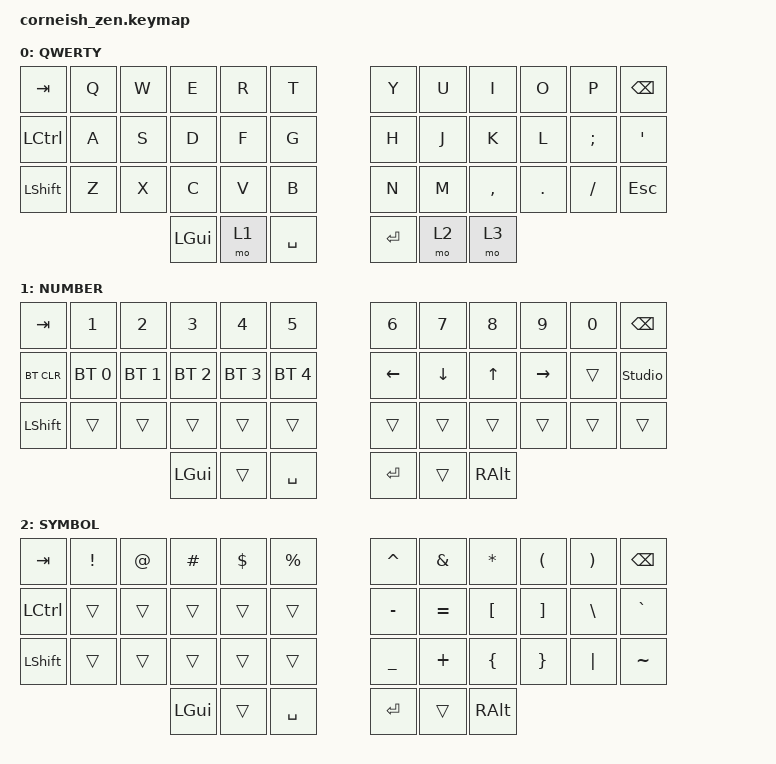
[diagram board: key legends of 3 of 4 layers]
#include <behaviors.dtsi>
#include <dt-bindings/zmk/keys.h>
#include <dt-bindings/zmk/bt.h>

/ {
    chosen {
        zmk,physical-layout = &foostan_corne_6col_layout;
        // zmk,physical-layout = &foostan_corne_5col_layout;
    };

    /* ========================== */
    /*  MACRO ALT-CODES WINDOWS   */
    /* ========================== */
    macros {
        /* Consigli: piccole attese rendono gli Alt-codes molto affidabili */
        /* à (Alt+0224)  /  À (Alt+0192) */
        agrave_alt: agrave_alt {
            compatible = "zmk,behavior-macro";
            #binding-cells = <0>;
            wait-ms = <40>; tap-ms = <40>;
            bindings = <&macro_press &kp LALT>,
                       <&macro_tap &kp KP_N0 &kp KP_N2 &kp KP_N2 &kp KP_N4>,
                       <&macro_release &kp LALT>;
        };
        Agrave_alt: Agrave_alt {
            compatible = "zmk,behavior-macro";
            #binding-cells = <0>;
            wait-ms = <40>; tap-ms = <40>;
            bindings = <&macro_press &kp LALT>,
                       <&macro_tap &kp KP_N0 &kp KP_N1 &kp KP_N9 &kp KP_N2>,
                       <&macro_release &kp LALT>;
        };

        /* è (Alt+0232)  /  È (Alt+0200) */
        egrave_alt: egrave_alt {
            compatible = "zmk,behavior-macro";
            #binding-cells = <0>;
            wait-ms = <40>; tap-ms = <40>;
            bindings = <&macro_press &kp LALT>,
                       <&macro_tap &kp KP_N0 &kp KP_N2 &kp KP_N3 &kp KP_N2>,
                       <&macro_release &kp LALT>;
        };
        Egrave_alt: Egrave_alt {
            compatible = "zmk,behavior-macro";
            #binding-cells = <0>;
            wait-ms = <40>; tap-ms = <40>;
            bindings = <&macro_press &kp LALT>,
                       <&macro_tap &kp KP_N0 &kp KP_N2 &kp KP_N0 &kp KP_N0>,
                       <&macro_release &kp LALT>;
        };

        /* ì (Alt+0236)  /  Ì (Alt+0204) */
        igrave_alt: igrave_alt {
            compatible = "zmk,behavior-macro";
            #binding-cells = <0>;
            wait-ms = <40>; tap-ms = <40>;
            bindings = <&macro_press &kp LALT>,
                       <&macro_tap &kp KP_N0 &kp KP_N2 &kp KP_N3 &kp KP_N6>,
                       <&macro_release &kp LALT>;
        };
        Igrave_alt: Igrave_alt {
            compatible = "zmk,behavior-macro";
            #binding-cells = <0>;
            wait-ms = <40>; tap-ms = <40>;
            bindings = <&macro_press &kp LALT>,
                       <&macro_tap &kp KP_N0 &kp KP_N2 &kp KP_N0 &kp KP_N4>,
                       <&macro_release &kp LALT>;
        };

        /* ò (Alt+0242)  /  Ò (Alt+0210) */
        ograve_alt: ograve_alt {
            compatible = "zmk,behavior-macro";
            #binding-cells = <0>;
            wait-ms = <40>; tap-ms = <40>;
            bindings = <&macro_press &kp LALT>,
                       <&macro_tap &kp KP_N0 &kp KP_N2 &kp KP_N4 &kp KP_N2>,
                       <&macro_release &kp LALT>;
        };
        Ograve_alt: Ograve_alt {
            compatible = "zmk,behavior-macro";
            #binding-cells = <0>;
            wait-ms = <40>; tap-ms = <40>;
            bindings = <&macro_press &kp LALT>,
                       <&macro_tap &kp KP_N0 &kp KP_N2 &kp KP_N1 &kp KP_N0>,
                       <&macro_release &kp LALT>;
        };

        /* ù (Alt+0249)  /  Ù (Alt+0217) */
        ugrave_alt: ugrave_alt {
            compatible = "zmk,behavior-macro";
            #binding-cells = <0>;
            wait-ms = <40>; tap-ms = <40>;
            bindings = <&macro_press &kp LALT>,
                       <&macro_tap &kp KP_N0 &kp KP_N2 &kp KP_N4 &kp KP_N9>,
                       <&macro_release &kp LALT>;
        };
        Ugrave_alt: Ugrave_alt {
            compatible = "zmk,behavior-macro";
            #binding-cells = <0>;
            wait-ms = <40>; tap-ms = <40>;
            bindings = <&macro_press &kp LALT>,
                       <&macro_tap &kp KP_N0 &kp KP_N2 &kp KP_N1 &kp KP_N7>,
                       <&macro_release &kp LALT>;
        };
    };

    /* ========================== */
    /*     MOD-MORPH (Shift)      */
    /* ========================== */
    behaviors {
        /* Se è premuto LSHIFT o RSHIFT ⇒ usa la versione maiuscola (macro corrispondente) */
        mm_agrave: mm_agrave {
            compatible = "zmk,behavior-mod-morph";
            #binding-cells = <0>;
            mods = <(MOD_LSFT|MOD_RSFT)>;
            bindings = <&agrave_alt>, <&Agrave_alt>;
        };
        mm_egrave: mm_egrave {
            compatible = "zmk,behavior-mod-morph";
            #binding-cells = <0>;
            mods = <(MOD_LSFT|MOD_RSFT)>;
            bindings = <&egrave_alt>, <&Egrave_alt>;
        };
        mm_igrave: mm_igrave {
            compatible = "zmk,behavior-mod-morph";
            #binding-cells = <0>;
            mods = <(MOD_LSFT|MOD_RSFT)>;
            bindings = <&igrave_alt>, <&Igrave_alt>;
        };
        mm_ograve: mm_ograve {
            compatible = "zmk,behavior-mod-morph";
            #binding-cells = <0>;
            mods = <(MOD_LSFT|MOD_RSFT)>;
            bindings = <&ograve_alt>, <&Ograve_alt>;
        };
        mm_ugrave: mm_ugrave {
            compatible = "zmk,behavior-mod-morph";
            #binding-cells = <0>;
            mods = <(MOD_LSFT|MOD_RSFT)>;
            bindings = <&ugrave_alt>, <&Ugrave_alt>;
        };
    };
};

 / {
    keymap {
        compatible = "zmk,keymap";

        default_layer {
            display-name = "QWERTY";
            // --------------------------------------------------------------------------------
            // |  TAB |  Q  |  W  |  E  |  R  |  T  |   |  Y  |  U   |  I  |  O  |  P  | BSPC |
            // | CTRL |  A  |  S  |  D  |  F  |  G  |   |  H  |  J   |  K  |  L  |  ;  |  '   |
            // | SHFT |  Z  |  X  |  C  |  V  |  B  |   |  N  |  M   |  ,  |  .  |  /  | ESC  |
            //                    | GUI | LWR | SPC |   | ENT | RSE  | ACC |
            // (ACC = &mo 3)
            bindings = <
&kp TAB   &kp Q &kp W &kp E &kp R &kp T   &kp Y &kp U  &kp I     &kp O   &kp P    &kp BSPC
&kp LCTRL &kp A &kp S &kp D &kp F &kp G   &kp H &kp J  &kp K     &kp L   &kp SEMI &kp SQT
&kp LSHFT &kp Z &kp X &kp C &kp V &kp B   &kp N &kp M  &kp COMMA &kp DOT &kp FSLH &kp ESC
               &kp LGUI &mo 1 &kp SPACE   &kp RET &mo 2 &mo 3
            >;
        };

        lower_layer {
            display-name = "NUMBER";
            // -----------------------------------------------------------------------------------------
            // |  TAB |  1  |  2  |  3  |  4  |  5  |   |  6  |  7  |  8  |  9  |  0  | BSPC |
            // | BTCLR| BT1 | BT2 | BT3 | BT4 | BT5 |   | LFT | DWN |  UP | RGT |     |Studio|
            // | SHFT |     |     |     |     |     |   |     |     |     |     |     |      |
            //                    | GUI |     | SPC |   | ENT |     | ALT |
            bindings = <
&kp TAB    &kp N1       &kp N2       &kp N3       &kp N4       &kp N5         &kp N6   &kp N7   &kp N8 &kp N9    &kp N0 &kp BSPC
&bt BT_CLR &bt BT_SEL 0 &bt BT_SEL 1 &bt BT_SEL 2 &bt BT_SEL 3 &bt BT_SEL 4   &kp LEFT &kp DOWN &kp UP &kp RIGHT &trans &studio_unlock
&kp LSHFT  &trans       &trans       &trans       &trans       &trans         &trans   &trans   &trans &trans    &trans &trans
                                     &kp LGUI     &trans       &kp SPACE      &kp RET  &trans   &kp RALT
            >;
        };

        raise_layer {
            display-name = "SYMBOL";
            // -----------------------------------------------------------------------------------------
            // |  TAB |  !  |  @  |  #  |  $  |  %  |   |  ^  |  &  |  *  |  (  |  )  | BSPC |
            // | CTRL |     |     |     |     |     |   |  -  |  =  |  [  |  ]  |  \  |  `   |
            // | SHFT |     |     |     |     |     |   |  _  |  +  |  {  |  }  | "|" |  ~   |
            //                    | GUI |     | SPC |   | ENT |     | ALT |
            bindings = <
&kp  TAB  &kp EXCL &kp AT &kp HASH &kp DLLR &kp PRCNT   &kp CARET &kp AMPS  &kp ASTRK &kp LPAR &kp RPAR &kp BSPC
&kp LCTRL &trans   &trans &trans   &trans   &trans      &kp MINUS &kp EQUAL &kp LBKT  &kp RBKT &kp BSLH &kp GRAVE
&kp LSHFT &trans   &trans &trans   &trans   &trans      &kp UNDER &kp PLUS  &kp LBRC  &kp RBRC &kp PIPE &kp TILDE
                          &kp LGUI &trans   &kp SPACE   &kp RET   &trans    &kp RALT
            >;
        };

        accent_layer {
            display-name = "ACCENTI";
            // --------------------------------------------------------------------------------------------------------------------
            // |      |     |     |  è/È |     |     |   |     |  ù/Ù |  ì/Ì |  ò/Ò |     |       |
            // |      |  à/À|     |      |     |     |   |     |      |      |      |     |       |
            // |      |     |     |      |     |     |   |     |      |      |      |     |       |
            //   (Shift premuto = MAIUSCOLE) – via mod-morph -> macro Alt
            //                    | GUI |     | SPC |   | ENT |     | (exit on release) |
            bindings = <
&trans   &trans &trans &mm_egrave &trans &trans      &trans  &trans   &mm_ugrave &mm_igrave &mm_ograve &trans &trans
&trans   &mm_agrave &trans &trans &trans &trans      &trans  &trans   &trans     &trans     &trans     &trans &trans
&trans   &trans &trans &trans &trans &trans          &trans  &trans   &trans     &trans     &trans     &trans &trans
                     &kp LGUI &trans &kp SPACE       &kp RET &trans   &trans
            >;
        };
    };
};
